AUTOSAR XML (schema 00048)
package /HuaweiMDC/FunctionalSoftware/Location/Execution
  executable LocationExecutable
    root sw component prototype LocationRootSwComponent: application-type=LocationApplicationSwComponent
package /HuaweiMDC/FunctionalSoftware/Location/SwComponent
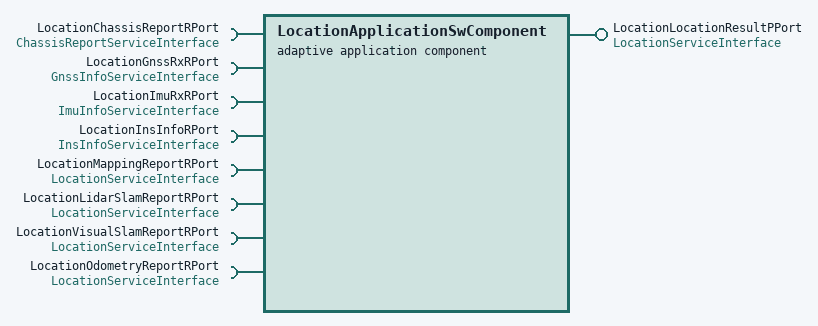
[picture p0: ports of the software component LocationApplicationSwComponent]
  adaptive application sw component type LocationApplicationSwComponent
    4 x require port:
      LocationChassisReportRPort: required-interface=ChassisReportServiceInterface
      LocationGnssRxRPort: required-interface=GnssInfoServiceInterface
      LocationImuRxRPort: required-interface=ImuInfoServiceInterface
      LocationInsInfoRPort: required-interface=InsInfoServiceInterface
    provide port LocationLocationResultPPort: provided-interface=LocationServiceInterface
    4 x require port, all with required-interface=LocationServiceInterface:
      LocationMappingReportRPort
      LocationLidarSlamReportRPort
      LocationVisualSlamReportRPort
      LocationOdometryReportRPort
